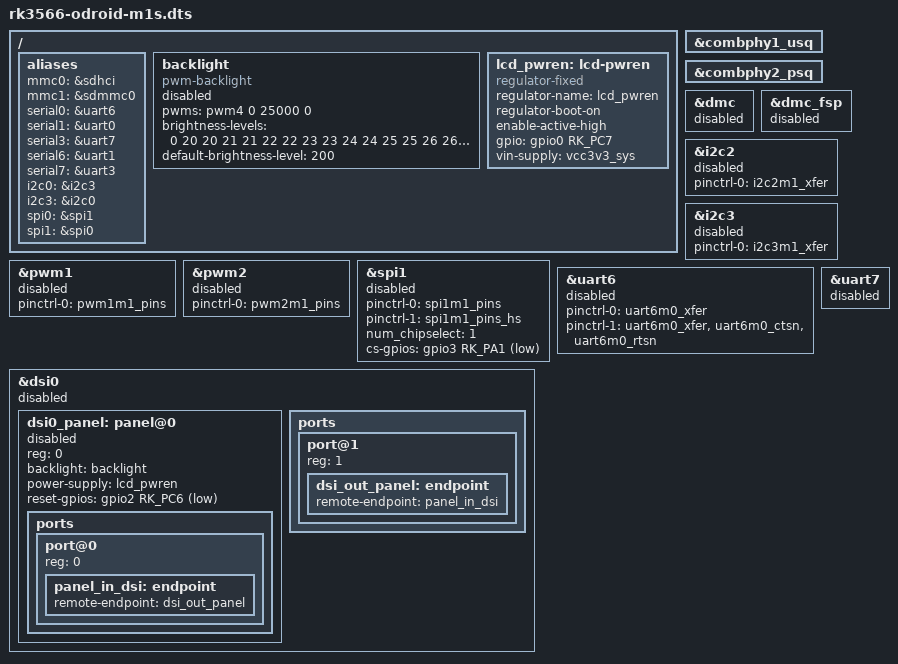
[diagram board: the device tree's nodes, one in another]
// SPDX-License-Identifier: (GPL-2.0+ OR MIT)
/*
 * Copyright (c) 2023 Hardkernel Co., Ltd.
 *
 */

#include "rk3566-odroid-m1s.dtsi"
#include "rk3568-android.dtsi"

/ {
	aliases {
		mmc0 = &sdhci;
		mmc1 = &sdmmc0;
		serial0 = &uart6;
		serial1 = &uart0;
		serial3 = &uart7;
		serial6 = &uart1;
		serial7 = &uart3;
		i2c0 = &i2c3;
		i2c3 = &i2c0;
		spi0 = &spi1;
		spi1 = &spi0;
	};

	backlight: backlight {
		compatible = "pwm-backlight";
		status = "disabled";

		pwms = <&pwm4 0 25000 0>;
		brightness-levels = <
			0  20  20  21  21  22  22  23
			23  24  24  25  25  26  26  27
			27  28  28  29  29  30  30  31
			31  32  32  33  33  34  34  35
			35  36  36  37  37  38  38  39
			40  41  42  43  44  45  46  47
			48  49  50  51  52  53  54  55
			56  57  58  59  60  61  62  63
			64  65  66  67  68  69  70  71
			72  73  74  75  76  77  78  79
			80  81  82  83  84  85  86  87
			88  89  90  91  92  93  94  95
			96  97  98  99 100 101 102 103
			104 105 106 107 108 109 110 111
			112 113 114 115 116 117 118 119
			120 121 122 123 124 125 126 127
			128 129 130 131 132 133 134 135
			136 137 138 139 140 141 142 143
			144 145 146 147 148 149 150 151
			152 153 154 155 156 157 158 159
			160 161 162 163 164 165 166 167
			168 169 170 171 172 173 174 175
			176 177 178 179 180 181 182 183
			184 185 186 187 188 189 190 191
			192 193 194 195 196 197 198 199
			200 201 202 203 204 205 206 207
			208 209 210 211 212 213 214 215
			216 217 218 219 220 221 222 223
			224 225 226 227 228 229 230 231
			232 233 234 235 236 237 238 239
			240 241 242 243 244 245 246 247
			248 249 250 251 252 253 254 255
			>;
		default-brightness-level = <200>;
	};

	lcd_pwren: lcd-pwren {
		compatible = "regulator-fixed";
		regulator-name = "lcd_pwren";
		regulator-boot-on;
		enable-active-high;
		gpio = <&gpio0 RK_PC7 GPIO_ACTIVE_HIGH>;
		vin-supply = <&vcc3v3_sys>;
	};
};

&combphy1_usq {
	status = "okay";
};

&combphy2_psq {
	status = "okay";
};

&dmc {
	status = "disabled";
};

&dmc_fsp {
	status = "disabled";
};

&i2c2 {
	status = "disabled";
	pinctrl-names = "default";
	pinctrl-0 = <&i2c2m1_xfer>;
};

&i2c3 {
	status = "disabled";
	pinctrl-names = "default";
	pinctrl-0 = <&i2c3m1_xfer>;
};

&pwm1 {
	status = "disabled";
	pinctrl-0 = <&pwm1m1_pins>;
};

&pwm2 {
	status = "disabled";
	pinctrl-0 = <&pwm2m1_pins>;
};

&spi1 {
	status = "disabled";

	pinctrl-0 = <&spi1m1_pins>;
	pinctrl-1 = <&spi1m1_pins_hs>;
	num_chipselect = <1>;

	cs-gpios = <&gpio3 RK_PA1 GPIO_ACTIVE_LOW>;
};

&uart6 {
	status = "disabled";
	dma-names = "tx", "rx";
	/* uart6 uart6-with-ctsrts */
	pinctrl-0 = <&uart6m0_xfer>;
	pinctrl-1 = <&uart6m0_xfer &uart6m0_ctsn &uart6m0_rtsn>;
};

&uart7 {
	status = "disabled";
};

&dsi0 {
	status = "disabled";
	#address-cells = <1>;
	#size-cells = <0>;
	dsi0_panel: panel@0 {
		status = "disabled";
		reg = <0>;
		backlight = <&backlight>;
		power-supply = <&lcd_pwren>;
		reset-gpios = <&gpio2 RK_PC6 GPIO_ACTIVE_LOW>;

		ports {
			#address-cells = <1>;
			#size-cells = <0>;

			port@0 {
				reg = <0>;
				panel_in_dsi: endpoint {
					remote-endpoint = <&dsi_out_panel>;
				};
			};
		};
	};
	ports {
		#address-cells = <1>;
		#size-cells = <0>;

		port@1 {
			reg = <1>;
			dsi_out_panel: endpoint {
				remote-endpoint = <&panel_in_dsi>;
			};
		};
	};
};
